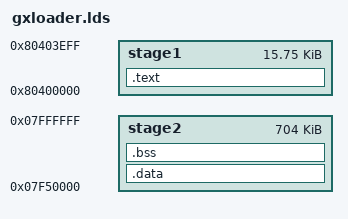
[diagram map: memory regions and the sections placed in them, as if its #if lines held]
#include "version_autogenerated.h"

MEMORY
{
	stage1	:	ORIGIN = 0x80400000,	LENGTH = 0x4000-256
	stage2	:	ORIGIN = 0x07f50000,       	LENGTH = 0xb0000
}

ENTRY(ResetEntry)
SECTIONS {
	. = ALIGN(4);
	.text :
	{
		_stage1_start_ = .;
		cpu/arm/canopus/canopus_start.o(.text*)
		cpu/arm/canopus/canopus_pll_mini.o(.text*)
		cpu/arm/canopus/canopus_pll_full.o(.text*)
		cpu/arm/canopus/canopus_sdram.o(.text*)
#ifdef CONFIG_DDR_SOFT_TRAINING
		cpu/arm/canopus/ddr_soft_training.o(.text*)
#endif
		cpu/copy.o(.text*)
		common/secure/common.o(.text*)
		cpu/arm/canopus/canopus_start.o(.rodata*)
		cpu/arm/canopus/canopus_pll_mini.o(.rodata*)
		cpu/arm/canopus/canopus_pll_full.o(.rodata*)
		cpu/arm/canopus/canopus_sdram.o(.rodata*)
#ifdef CONFIG_DDR_SOFT_TRAINING
		cpu/arm/canopus/ddr_soft_training.o(.rodata*)
#endif
		cpu/copy.o(.rodata*)
		common/secure/common.o(.rodata*)
		cpu/arm/canopus/canopus_start.o(.data*)
		cpu/arm/canopus/canopus_pll_mini.o(.data*)
		cpu/arm/canopus/canopus_pll_full.o(.data*)
		cpu/arm/canopus/canopus_sdram.o(.data*)
#ifdef CONFIG_DDR_SOFT_TRAINING
		cpu/arm/canopus/ddr_soft_training.o(.data*)
#endif
		cpu/copy.o(.data*)
		common/secure/common.o(.data*)
		*(.cache_section)
		*(.reset_patch)
		*(.sram_text)
		*(.sram)
#ifdef CONFIG_ENABLE_MEMORY_PHASE_TEST
		test/memory/memphase_test.o(.text*)
		test/memory/memphase_test.o(.data*)
		test/memory/memphase_test.o(.rodata*)
#elif defined(CONFIG_ENABLE_MEMORY_TEST)
		test/memory/mem_test.o(.text*)
		test/memory/mem_test.o(.data*)
		test/memory/mem_test.o(.rodata*)
#endif
#ifdef ENABLE_SECURE_VERIFY
		common/secure/common.o(.text*)
		common/hash.o(.text*)
		drivers/hash/gx_sha256.o(.text*)
		common/secure/common.o(.rodata*)
		common/hash.o(.rodata*)
		drivers/hash/gx_sha256.o(.rodata*)
		common/secure/common.o(.data*)
		common/hash.o(.data*)
		drivers/hash/gx_sha256.o(.data*)
#ifdef CONFIG_PKA
		common/secure/pka/dw_pka.o(.text*)
		common/secure/pka/dw_pka.o(.rodata*)
		common/secure/pka/dw_pka.o(.data*)
#endif
#ifdef CONFIG_SECURE_VERIFY_TYPE_SM2
		common/secure/sm2/sm2_verify.o(.text*)
		common/secure/sm2/sm2_verify.o(.rodata*)
		common/secure/sm2/sm2_verify.o(.data*)
#elif defined(CONFIG_SECURE_VERIFY_TYPE_RSA_SMI) || defined(CONFIG_SECURE_VERIFY_TYPE_RSA_PKCS)
		common/secure/rsa/rsa.o(.text*)
		common/secure/rsa/rsa_verify.o(.text*)
		common/secure/rsa/rsa.o(.rodata*)
		common/secure/rsa/rsa_verify.o(.rodata*)
		common/secure/rsa/rsa.o(.data*)
		common/secure/rsa/rsa_verify.o(.data*)
#endif
#endif

#ifdef ENABLE_STAGE2_ENCRYPT
		common/secure/decrypt/decrypt.o(.text*)
		common/secure/decrypt/gx_acpu_decrypt.o(.text*)
		common/secure/decrypt/decrypt.o(.rodata*)
		common/secure/decrypt/gx_acpu_decrypt.o(.rodata*)
		common/secure/decrypt/decrypt.o(.data*)
		common/secure/decrypt/gx_acpu_decrypt.o(.data*)
#endif
		_stage1_end_ = .;
	} > stage1

	. = ALIGN(2048);
	.data :
	{
		_stage2_start_ = .;
		_stage2_text_start_ = .;
		*(.irq_text)
		. = ALIGN(512);
		*(.fiq_text)
		. = ALIGN(512);
		*(.entry_text)
		. = ALIGN(4);
		*(.text*)
		. = ALIGN(4);
		_stage2_text_end_ = .;
		__commands_begin = .;
		KEEP(*(.data.commands))
		. = ALIGN(4);
		__commands_end = .;
		_stage2_data_start_ = .;
		*(.data*)
		*(.rodata*)
		. = ALIGN(16);
		_stage2_data_end_ = .;
		_stage2_end_ = .;
	} > stage2
	
	. = ALIGN(4);
	.bss :
	{
		. = ALIGN(4);
		__bss_start__ = .;
		*(.bss*)
		*(COMMON)
		. = ALIGN(4);
		__bss_end__ = .;
	} > stage2

}

